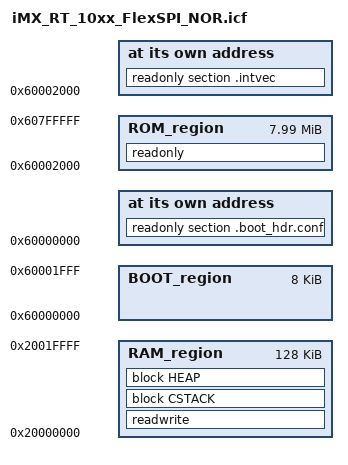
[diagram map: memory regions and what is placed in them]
/* iMX_RT_10xx_FlexSPI_NOR.icf - for iMX RT 10xx running from FlexSPI NOR */
/* 128k SRAM data                                                         */
define symbol __ICFEDIT_boot_config__       = 0x60000000;
define symbol __ICFEDIT_ivt__               = 0x60001000;
define symbol __ICFEDIT_boot_data__         = 0x60001020;
define symbol __ICFEDIT_key__               = 0x60001fb0;
define symbol __ICFEDIT_init__              = 0x60001fe0;
define symbol __ICFEDIT_intvec_start__      = 0x60002000;
/*-Memory Regions-*/
define symbol __ICFEDIT_region_BOOT_start__ = 0x60000000;
define symbol __ICFEDIT_region_BOOT_end__   = 0x60001FFF;
define symbol __ICFEDIT_region_ROM_start__  = 0x60002000;
define symbol __ICFEDIT_region_ROM_end__    = 0x607FFFFF;
define symbol __ICFEDIT_region_IRAM_start__ = 0x00000300;    /* 0x300 reserved for interrupt vectors */
define symbol __ICFEDIT_region_IRAM_end__   = 0x0000FFFF;
define symbol __ICFEDIT_region_RAM_start__  = 0x20000000;
define symbol __ICFEDIT_region_RAM_end__    = 0x2001FFFF;
/*-Sizes-*/
define symbol __ICFEDIT_size_cstack__ = 0x0;
define symbol __ICFEDIT_size_heap__   = 0x0;
/**** End of ICF editor section. ###ICF###*/


define memory mem with size = 4G;
define region BOOT_region  = mem:[from __ICFEDIT_region_BOOT_start__ to __ICFEDIT_region_BOOT_end__];
define region ROM_region   = mem:[from __ICFEDIT_region_ROM_start__ to  __ICFEDIT_region_ROM_end__];
define region RAM_region   = mem:[from __ICFEDIT_region_RAM_start__ to  __ICFEDIT_region_RAM_end__];

define block CSTACK    with alignment = 8, size = __ICFEDIT_size_cstack__   { };
define block HEAP      with alignment = 8, size = __ICFEDIT_size_heap__     { };

initialize by copy { readwrite };
do not initialize  { section .noinit };

place at address mem:__ICFEDIT_boot_config__ { readonly section .boot_hdr.conf };
place at address __ICFEDIT_ivt__ { readonly section .boot_hdr.ivt };
place at address __ICFEDIT_boot_data__ { readonly section .boot_hdr.dcd_data };
place at address __ICFEDIT_key__ { readonly section .boot_hdr.key };
place at address __ICFEDIT_init__ { readonly section .boot_hdr.init };
place at address mem:__ICFEDIT_intvec_start__ { readonly section .intvec };


place in ROM_region   { readonly };
place in RAM_region   { readwrite, block CSTACK, block HEAP };
